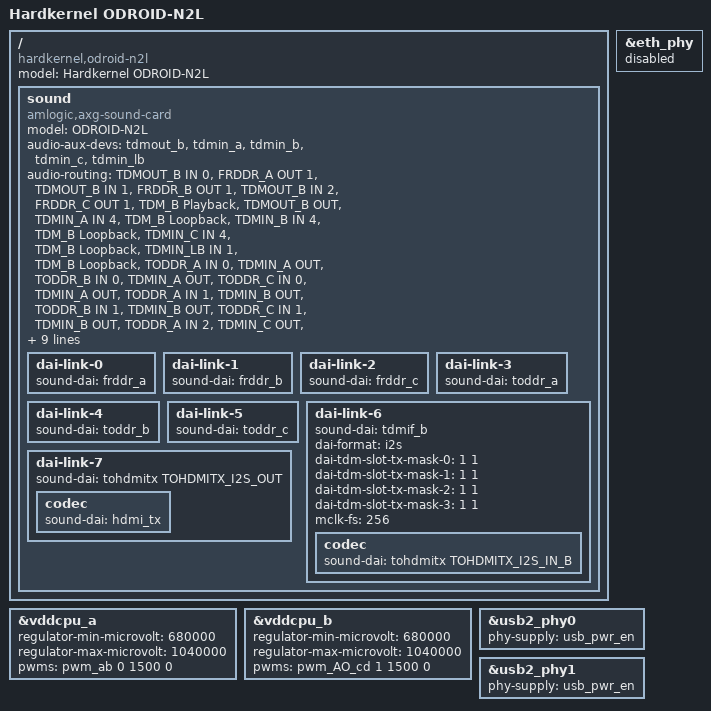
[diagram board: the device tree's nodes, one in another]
// SPDX-License-Identifier: (GPL-2.0+ OR MIT)
/*
 * Copyright (c) 2022 Dongjin Kim <tobetter@gmail.com>
 */

/dts-v1/;

/* The Amlogic S922X Rev. C supports the same OPPs as the A311D variant */
#include "meson-g12b-a311d.dtsi"
#include "meson-g12b-odroid.dtsi"

/ {
	compatible = "hardkernel,odroid-n2l", "amlogic,s922x", "amlogic,g12b";
	model = "Hardkernel ODROID-N2L";

	sound {
		compatible = "amlogic,axg-sound-card";
		model = "ODROID-N2L";
		audio-aux-devs = <&tdmout_b>, <&tdmin_a>, <&tdmin_b>,
				 <&tdmin_c>, <&tdmin_lb>;
		audio-routing = "TDMOUT_B IN 0", "FRDDR_A OUT 1",
				"TDMOUT_B IN 1", "FRDDR_B OUT 1",
				"TDMOUT_B IN 2", "FRDDR_C OUT 1",
				"TDM_B Playback", "TDMOUT_B OUT",
				"TDMIN_A IN 4", "TDM_B Loopback",
				"TDMIN_B IN 4", "TDM_B Loopback",
				"TDMIN_C IN 4", "TDM_B Loopback",
				"TDMIN_LB IN 1", "TDM_B Loopback",
				"TODDR_A IN 0", "TDMIN_A OUT",
				"TODDR_B IN 0", "TDMIN_A OUT",
				"TODDR_C IN 0", "TDMIN_A OUT",
				"TODDR_A IN 1", "TDMIN_B OUT",
				"TODDR_B IN 1", "TDMIN_B OUT",
				"TODDR_C IN 1", "TDMIN_B OUT",
				"TODDR_A IN 2", "TDMIN_C OUT",
				"TODDR_B IN 2", "TDMIN_C OUT",
				"TODDR_C IN 2", "TDMIN_C OUT",
				"TODDR_A IN 6", "TDMIN_LB OUT",
				"TODDR_B IN 6", "TDMIN_LB OUT",
				"TODDR_C IN 6", "TDMIN_LB OUT";

		assigned-clocks = <&clkc CLKID_MPLL2>,
				  <&clkc CLKID_MPLL0>,
				  <&clkc CLKID_MPLL1>;
		assigned-clock-parents = <0>, <0>, <0>;
		assigned-clock-rates = <294912000>,
				       <270950400>,
				       <393216000>;

		dai-link-0 {
			sound-dai = <&frddr_a>;
		};

		dai-link-1 {
			sound-dai = <&frddr_b>;
		};

		dai-link-2 {
			sound-dai = <&frddr_c>;
		};

		dai-link-3 {
			sound-dai = <&toddr_a>;
		};

		dai-link-4 {
			sound-dai = <&toddr_b>;
		};

		dai-link-5 {
			sound-dai = <&toddr_c>;
		};

		/* 8ch hdmi interface */
		dai-link-6 {
			sound-dai = <&tdmif_b>;
			dai-format = "i2s";
			dai-tdm-slot-tx-mask-0 = <1 1>;
			dai-tdm-slot-tx-mask-1 = <1 1>;
			dai-tdm-slot-tx-mask-2 = <1 1>;
			dai-tdm-slot-tx-mask-3 = <1 1>;
			mclk-fs = <256>;

			codec {
				sound-dai = <&tohdmitx TOHDMITX_I2S_IN_B>;
			};
		};

		/* hdmi glue */
		dai-link-7 {
			sound-dai = <&tohdmitx TOHDMITX_I2S_OUT>;

			codec {
				sound-dai = <&hdmi_tx>;
			};
		};
	};
};

&eth_phy {
	status = "disabled";
};

&vddcpu_a {
	regulator-min-microvolt = <680000>;
	regulator-max-microvolt = <1040000>;

	pwms = <&pwm_ab 0 1500 0>;
};

&vddcpu_b {
	regulator-min-microvolt = <680000>;
	regulator-max-microvolt = <1040000>;

	pwms = <&pwm_AO_cd 1 1500 0>;
};

&usb2_phy0 {
	phy-supply = <&usb_pwr_en>;
};

&usb2_phy1 {
	phy-supply = <&usb_pwr_en>;
};
